# STM32N645 register map
File version: 1.0
CPU: CM55 r0p1, little endian, no MPU, FPU, vendor SysTick, 8 interrupt priority bits
Registers are 32-bit, read-write, reset 0x0 unless marked. A register's access mark holds for its fields unless they carry their own. Offsets are from the block's base; [hi:lo] are bit positions; {n}, {i} and the like mark numbered series.

## FDCAN1 — FDCAN register block
Base 0x4000A000
Same registers: FDCAN2 0x4000A400, FDCAN3 0x4000E800, FDCAN1_S 0x5000A000, FDCAN2_S 0x5000A400, FDCAN3_S 0x5000E800
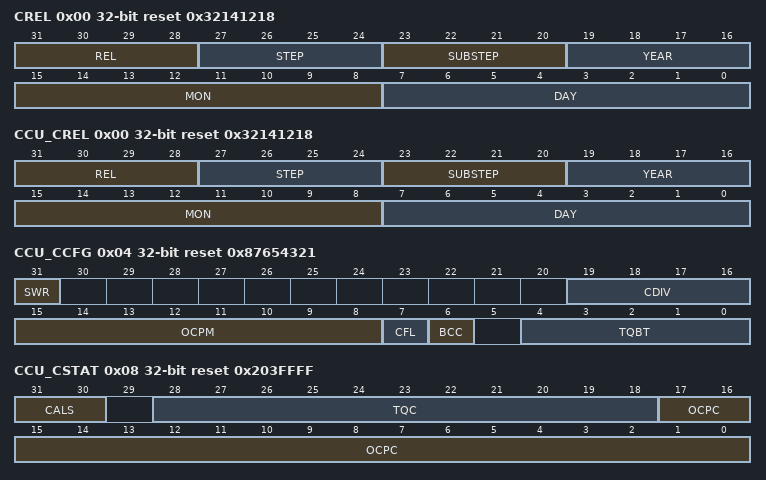
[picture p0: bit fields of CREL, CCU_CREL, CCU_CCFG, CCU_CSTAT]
0x00 CREL ro reset 0x32141218 — FDCAN core release register
  [31:28] REL — Core release = 3
  [27:24] STEP — Step of core release = 2
  [23:20] SUBSTEP — Sub-step of core release = 1
  [19:16] YEAR — Timestamp year = 4
  [15:8] MON — Timestamp month = 12
  [7:0] DAY — Timestamp day =18
0x00 CCU_CREL ro reset 0x32141218 (alternate view of CREL) — FDCAN core release register
  [31:28] REL — Core release = 1
  [27:24] STEP — Step of core release = 1
  [23:20] SUBSTEP — Sub-step of core release = 1
  [19:16] YEAR — Timestamp year =
  [15:8] MON — Timestamp month = 12
  [7:0] DAY — Timestamp day = 18
0x04 ENDN ro reset 0x87654321 — FDCAN Endian register
  [31:0] ETV — Endiannes Test value
0x04 CCU_CCFG reset 0x87654321 (alternate view of ENDN) — FDCAN Endian register
  [31] SWR — Software reset
  [19:16] CDIV — Clock divider
  [15:8] OCPM — Oscillator clock periods minimum
  [7] CFL — Calibration field length
  [6] BCC — Bypass clock calibration
  [4:0] TQBT — Time quanta per bit time
0x08 CCU_CSTAT ro reset 0x203FFFF — Calibration status register
  [31:30] CALS — Calibration state
  [28:18] TQC — Time quanta counter
  [17:0] OCPC — Oscillator clock period counter
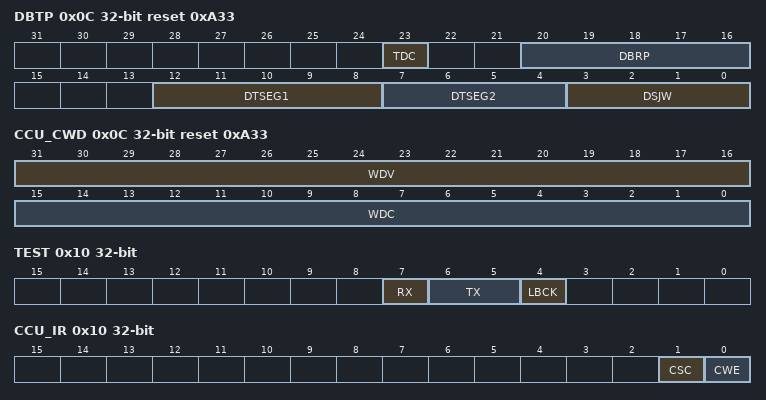
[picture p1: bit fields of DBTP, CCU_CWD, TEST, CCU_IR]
0x0C DBTP reset 0xA33 — FDCAN data bit timing and prescaler register
  [23] TDC — Transceiver delay compensation
  [20:16] DBRP — Data bitrate prescaler
  [12:8] DTSEG1 — Data time segment before sample point
  [7:4] DTSEG2 — Data time segment after sample point
  [3:0] DSJW — Synchronization jump width
0x0C CCU_CWD access per field reset 0xA33 (alternate view of DBTP) — FDCAN data bit timing and prescaler register
  [31:16] WDV ro — Watchdog value
  [15:0] WDC rw
0x10 TEST access per field — FDCAN test register
  [7] RX ro — Receive pin
  [6:5] TX rw — Control of transmit pin
  [4] LBCK rw — Loop back mode
0x10 CCU_IR (alternate view of TEST) — FDCAN test register
  [1] CSC — Calibration state changed
  [0] CWE — Calibration watchdog event
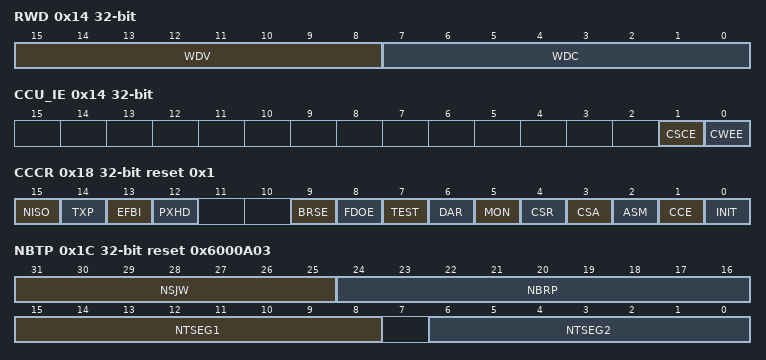
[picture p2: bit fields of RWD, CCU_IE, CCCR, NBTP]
0x14 RWD access per field — FDCAN RAM watchdog register
  [15:8] WDV ro — Watchdog value
  [7:0] WDC rw — Watchdog configuration
0x14 CCU_IE (alternate view of RWD) — FDCAN RAM watchdog register
  [1] CSCE — Calibration state changed enable
  [0] CWEE — Calibration watchdog event enable
0x18 CCCR access per field reset 0x1 — FDCAN CC control register
  [15] NISO rw — Non ISO operation
  [14] TXP rw — If this bit is set, the FDCAN pauses for two CAN bit times before starting the next transmission after successfully transmitting a frame.
  [13] EFBI rw — Edge filtering during bus integration
  [12] PXHD rw — Protocol exception handling disable
  [9] BRSE rw — FDCAN bitrate switching
  [8] FDOE rw — FD operation enable
  [7] TEST rw — Test mode enable
  [6] DAR rw — Disable automatic retransmission
  [5] MON rw — Bus monitoring mode
  [4] CSR rw — Clock stop request
  [3] CSA ro — Clock stop acknowledge
  [2] ASM rw — ASM restricted operation mode
  [1] CCE rw — Configuration change enable
  [0] INIT rw — Initialization
0x1C NBTP reset 0x6000A03 — FDCAN nominal bit timing and prescaler register
  [31:25] NSJW — Nominal (re)synchronization jump width
  [24:16] NBRP — Bitrate prescaler
  [15:8] NTSEG1 — Nominal time segment before sample point
  [6:0] NTSEG2 — Nominal time segment after sample point
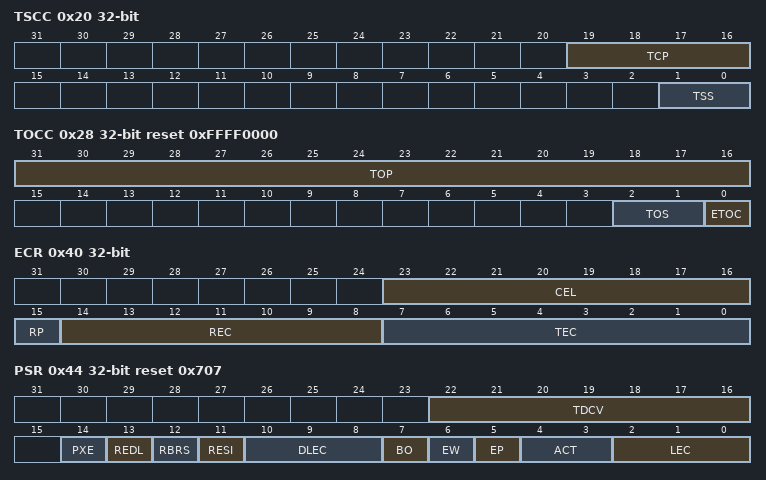
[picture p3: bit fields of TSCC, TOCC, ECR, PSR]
0x20 TSCC — FDCAN timestamp counter configuration register
  [19:16] TCP — Timestamp counter prescaler
  [1:0] TSS — Timestamp select
0x24 TSCV — FDCAN timestamp counter value register
  [15:0] TSC — Timestamp counter
0x28 TOCC reset 0xFFFF0000 — FDCAN timeout counter configuration register
  [31:16] TOP — Timeout period
  [2:1] TOS — Timeout select
  [0] ETOC — Enable timeout counter
0x2C TOCV reset 0xFFFF — FDCAN timeout counter value register
  [15:0] TOC — Timeout counter
0x40 ECR access per field — FDCAN error counter register
  [23:16] CEL rw — CAN error logging
  [15] RP ro — Receive error passive
  [14:8] REC ro — Receive error counter
  [7:0] TEC ro — Transmit error counter
0x44 PSR access per field reset 0x707 — FDCAN protocol status register
  [22:16] TDCV ro — Transmitter delay compensation value
  [14] PXE rw — Protocol exception event
  [13] REDL rw — Received FDCAN message
  [12] RBRS rw — BRS flag of last received FDCAN message
  [11] RESI rw — ESI flag of last received FDCAN message
  [10:8] DLEC ro — Data last error code
  [7] BO ro — Bus_Off status
  [6] EW ro — Warning status
  [5] EP ro — Error passive
  [4:3] ACT ro — Activity
  [2:0] LEC ro — Last error code
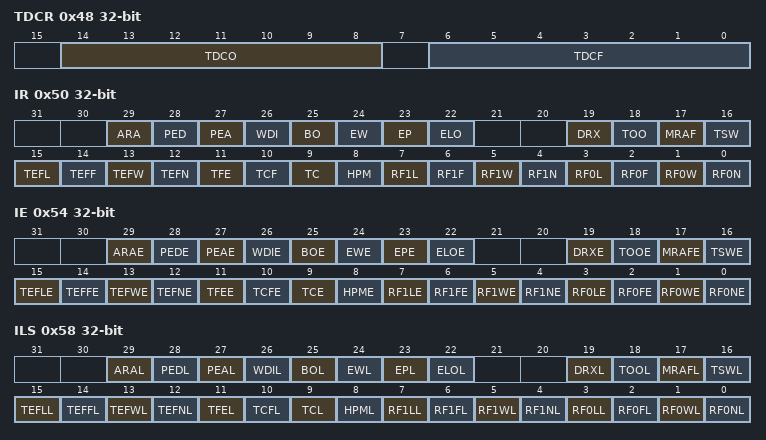
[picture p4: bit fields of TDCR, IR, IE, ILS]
0x48 TDCR — FDCAN transmitter delay compensation register
  [14:8] TDCO — Transmitter delay compensation offset
  [6:0] TDCF — Transmitter delay compensation filter window length
0x50 IR — FDCAN interrupt register
  [29] ARA — Access to reserved address
  [28] PED — Protocol error in data phase (data bit time is used)
  [27] PEA — Protocol error in arbitration phase (nominal bit time is used)
  [26] WDI — Watchdog interrupt
  [25] BO — Bus_Off status
  [24] EW — Warning status
  [23] EP — Error passive
  [22] ELO — Error logging overflow
  [19] DRX — Message stored to dedicated Rx buffer
  [18] TOO — Timeout occurred
  [17] MRAF — Message RAM access failure
  [16] TSW — Timestamp wraparound
  [15] TEFL — Tx event FIFO element lost
  [14] TEFF — Tx event FIFO full
  [13] TEFW — Tx event FIFO watermark reached
  [12] TEFN — Tx event FIFO new entry
  [11] TFE — Tx FIFO empty
  [10] TCF — Transmission cancellation finished
  [9] TC — Transmission completed
  [8] HPM — High priority message
  [7] RF1L — Rx FIFO 1 message lost
  [6] RF1F — Rx FIFO 1 full
  [5] RF1W — Rx FIFO 1 watermark reached
  [4] RF1N — Rx FIFO 1 new message
  [3] RF0L — Rx FIFO 0 message lost
  [2] RF0F — Rx FIFO 0 full
  [1] RF0W — Rx FIFO 0 watermark reached
  [0] RF0N — Rx FIFO 0 New message
0x54 IE — FDCAN interrupt enable register
  [29] ARAE — Access to Reserved address enable
  [28] PEDE — Protocol error in data phase enable
  [27] PEAE — Protocol error in Arbitration phase enable
  [26] WDIE — Watchdog interrupt enable
  [25] BOE — Bus_Off status
  [24] EWE — Warning status interrupt enable
  [23] EPE — Error passive interrupt enable
  [22] ELOE — Error logging overflow interrupt enable
  [19] DRXE — Message stored to dedicated Rx buffer interrupt enable
  [18] TOOE — Timeout occurred interrupt enable
  [17] MRAFE — Message RAM access failure interrupt enable
  [16] TSWE — Timestamp wraparound interrupt enable
  [15] TEFLE — Tx event FIFO element lost interrupt enable
  [14] TEFFE — Tx event FIFO full interrupt enable
  [13] TEFWE — Tx event FIFO watermark reached interrupt enable
  [12] TEFNE — Tx event FIFO new entry interrupt enable
  [11] TFEE — Tx FIFO empty interrupt enable
  [10] TCFE — Transmission cancellation finished interrupt enable
  [9] TCE — Transmission completed interrupt enable
  [8] HPME — High priority message interrupt enable
  [7] RF1LE — Rx FIFO 1 message lost interrupt enable
  [6] RF1FE — Rx FIFO 1 full interrupt enable
  [5] RF1WE — Rx FIFO 1 watermark reached interrupt enable
  [4] RF1NE — Rx FIFO 1 new message interrupt enable
  [3] RF0LE — Rx FIFO 0 message lost interrupt enable
  [2] RF0FE — Rx FIFO 0 full interrupt enable
  [1] RF0WE — Rx FIFO 0 watermark reached interrupt enable
  [0] RF0NE — Rx FIFO 0 new message interrupt enable
0x58 ILS — FDCAN interrupt line select register
  [29] ARAL — Access to reserved address line
  [28] PEDL — Protocol error in data phase line
  [27] PEAL — Protocol error in arbitration phase line
  [26] WDIL — Watchdog interrupt line
  [25] BOL — Bus_Off status
  [24] EWL — Warning status interrupt line
  [23] EPL — Error passive interrupt line
  [22] ELOL — Error logging overflow interrupt line
  [19] DRXL — Message stored to dedicated Rx buffer interrupt line
  [18] TOOL — Timeout occurred interrupt line
  [17] MRAFL — Message RAM access failure interrupt line
  [16] TSWL — Timestamp wraparound interrupt line
  [15] TEFLL — Tx event FIFO element Lost interrupt line
  [14] TEFFL — Tx event FIFO full interrupt line
  [13] TEFWL — Tx event FIFO watermark reached interrupt line
  [12] TEFNL — Tx event FIFO new entry interrupt line
  [11] TFEL — Tx FIFO empty interrupt line
  [10] TCFL — Transmission cancellation finished interrupt line
  [9] TCL — Transmission completed interrupt line
  [8] HPML — High priority message interrupt line
  [7] RF1LL — Rx FIFO 1 message lost interrupt line
  [6] RF1FL — Rx FIFO 1 full interrupt line
  [5] RF1WL — Rx FIFO 1 watermark reached interrupt line
  [4] RF1NL — Rx FIFO 1 new message interrupt line
  [3] RF0LL — Rx FIFO 0 message lost interrupt line
  [2] RF0FL — Rx FIFO 0 full interrupt line
  [1] RF0WL — Rx FIFO 0 watermark reached interrupt line
  [0] RF0NL — Rx FIFO 0 new message interrupt line
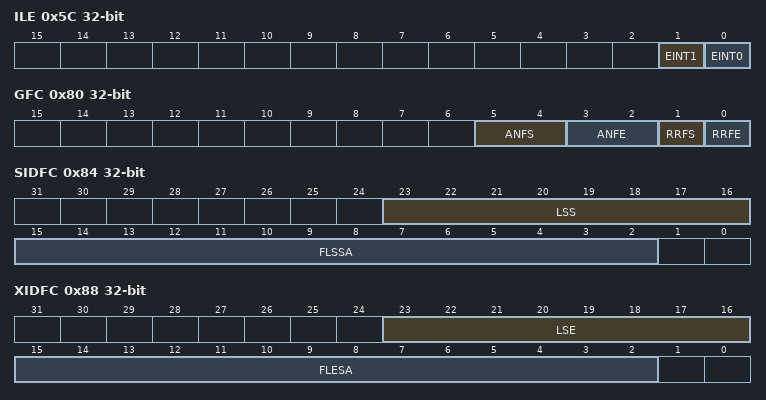
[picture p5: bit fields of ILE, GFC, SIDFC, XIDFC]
0x5C ILE — FDCAN interrupt line enable register
  [1] EINT1 — Enable interrupt line 1
  [0] EINT0 — Enable interrupt line 0
0x80 GFC — FDCAN global filter configuration register
  [5:4] ANFS — Accept non-matching frames standard
  [3:2] ANFE — Accept non-matching frames extended
  [1] RRFS — Reject remote frames standard
  [0] RRFE — Reject remote frames extended
0x84 SIDFC — FDCAN standard ID filter configuration register
  [23:16] LSS — List size standard
  [15:2] FLSSA — Filter list standard start address
0x88 XIDFC — FDCAN extended ID filter configuration register
  [23:16] LSE — List size extended
  [15:2] FLESA — Filter list extended start address
0x90 XIDAM reset 0x1FFFFFFF — FDCAN extended ID and mask register
  [28:0] EIDM — Extended ID Mask
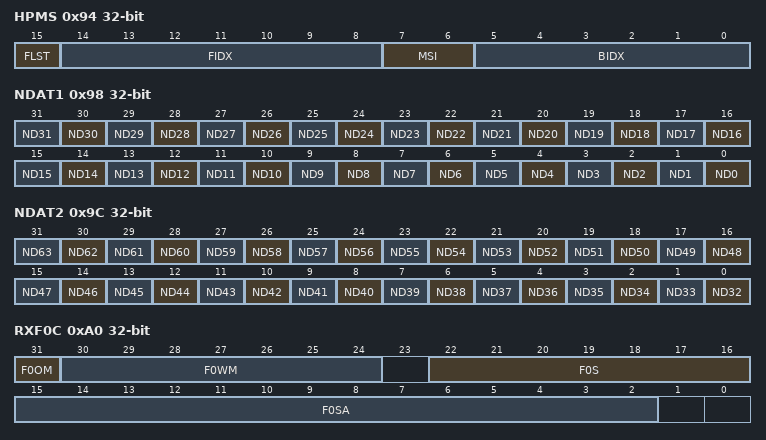
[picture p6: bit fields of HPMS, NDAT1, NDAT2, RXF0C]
0x94 HPMS ro — FDCAN high priority message status register
  [15] FLST — Filter list
  [14:8] FIDX — Filter index
  [7:6] MSI — Message storage indicator
  [5:0] BIDX — Buffer index
0x98 NDAT1 — FDCAN new data 1 register
  [n] ND{n} (n=0..31) — New data[31:0]
0x9C NDAT2 — FDCAN new data 2 register
  [n-32] ND{n} (n=32..63) — New data[63:32]
0xA0 RXF0C — FDCAN Rx FIFO 0 configuration register
  [31] F0OM — FIFO 0 operation mode
  [30:24] F0WM — FIFO 0 watermark
  [22:16] F0S — Rx FIFO 0 size
  [15:2] F0SA — Rx FIFO 0 start address
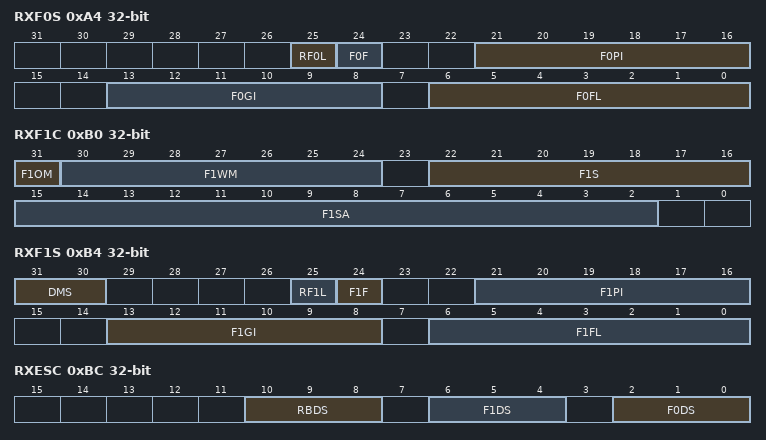
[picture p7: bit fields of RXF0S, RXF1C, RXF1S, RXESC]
0xA4 RXF0S — FDCAN Rx FIFO 0 status register
  [25] RF0L — Rx FIFO 0 message lost
  [24] F0F — Rx FIFO 0 full
  [21:16] F0PI — Rx FIFO 0 put index
  [13:8] F0GI — Rx FIFO 0 get index
  [6:0] F0FL — Rx FIFO 0 fill level
0xA8 RXF0A — FDCAN Rx FIFO 0 acknowledge register
  [5:0] F0AI — Rx FIFO 0 acknowledge index
0xAC RXBC — FDCAN Rx buffer configuration register
  [15:2] RBSA — Rx buffer start address
0xB0 RXF1C — FDCAN Rx FIFO 1 configuration register
  [31] F1OM — FIFO 1 operation mode
  [30:24] F1WM — Rx FIFO 1 watermark
  [22:16] F1S — Rx FIFO 1 size
  [15:2] F1SA — Rx FIFO 1 start address
0xB4 RXF1S ro — FDCAN Rx FIFO 1 status register
  [31:30] DMS — Debug message status
  [25] RF1L — Rx FIFO 1 message lost
  [24] F1F — Rx FIFO 1 full
  [21:16] F1PI — Rx FIFO 1 put index
  [13:8] F1GI — Rx FIFO 1 get index
  [6:0] F1FL — Rx FIFO 1 fill level
0xB8 RXF1A — FDCAN Rx FIFO 1 acknowledge register
  [5:0] F1AI — Rx FIFO 1 acknowledge index
0xBC RXESC ro — FDCAN Rx buffer element size configuration register
  [10:8] RBDS — Rx buffer data field size
  [6:4] F1DS — Rx FIFO 0 data field size
  [2:0] F0DS — Rx FIFO 1 data field size
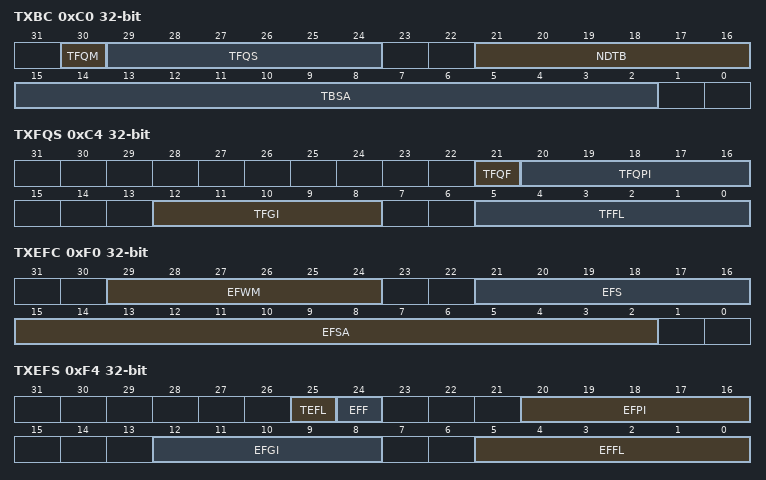
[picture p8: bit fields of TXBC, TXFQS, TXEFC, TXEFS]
0xC0 TXBC — FDCAN Tx buffer configuration register
  [30] TFQM — Tx FIFO/queue mode
  [29:24] TFQS — Transmit FIFO/queue size
  [21:16] NDTB — Number of dedicated transmit buffers
  [15:2] TBSA — Tx buffers start address
0xC4 TXFQS ro — FDCAN Tx FIFO/queue status register
  [21] TFQF — Tx FIFO/queue full
  [20:16] TFQPI — Tx FIFO/queue put index
  [12:8] TFGI — Tx FIFO get index.
  [5:0] TFFL — Tx FIFO free level
0xC8 TXESC ro — FDCAN Tx buffer element size configuration register
  [2:0] TBDS — Tx buffer data Field size:
0xCC TXBRP ro — FDCAN Tx buffer request pending register
  [31:0] TRP — Transmission request pending
0xD0 TXBAR — FDCAN Tx buffer add request register
  [31:0] AR — Add request
0xD4 TXBCR — FDCAN Tx buffer cancellation request register
  [31:0] CR — Cancellation request
0xD8 TXBTO ro — FDCAN Tx buffer transmission occurred register
  [31:0] TO — Transmission occurred
0xDC TXBCF ro — FDCAN Tx buffer cancellation finished register
  [31:0] CF — Cancellation finished
0xE0 TXBTIE — FDCAN Tx buffer transmission interrupt enable register
  [31:0] TIE — Transmission interrupt enable
0xE4 TXBCIE — FDCAN Tx buffer cancellation finished interrupt enable register
  [31:0] CFIE — Cancellation finished interrupt enable
0xF0 TXEFC — FDCAN Tx event FIFO configuration register
  [29:24] EFWM — Event FIFO watermark
  [21:16] EFS — Event FIFO size.
  [15:2] EFSA — Event FIFO start address
0xF4 TXEFS ro — FDCAN Tx event FIFO status register
  [25] TEFL — Tx event FIFO element lost
  [24] EFF — Event FIFO full
  [20:16] EFPI — Event FIFO put index
  [12:8] EFGI — Event FIFO get index
  [5:0] EFFL — Event FIFO fill level
0xF8 TXEFA — FDCAN Tx event FIFO acknowledge register
  [4:0] EFAI — Event FIFO acknowledge index
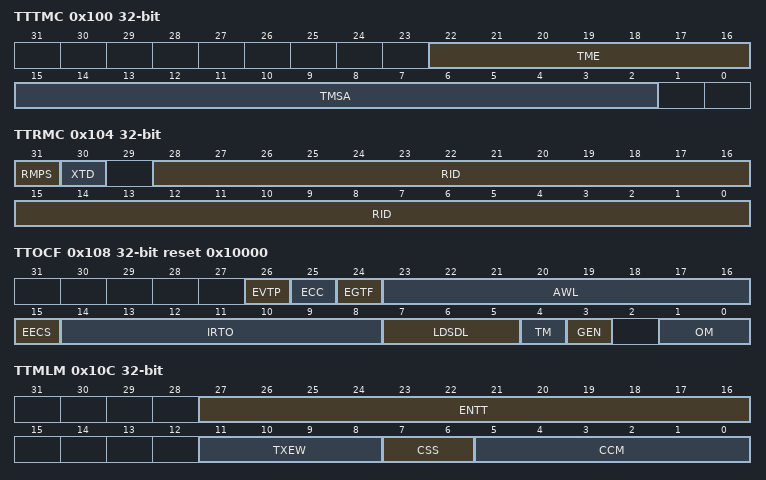
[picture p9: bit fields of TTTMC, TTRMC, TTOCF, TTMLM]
0x100 TTTMC — FDCAN TT trigger memory configuration register
  [22:16] TME — Trigger memory elements
  [15:2] TMSA — Trigger memory start address.
0x104 TTRMC — FDCAN TT reference message configuration register
  [31] RMPS — Reference message payload select
  [30] XTD — Extended identifier
  [28:0] RID — Reference identifier.
0x108 TTOCF reset 0x10000 — FDCAN TT operation configuration register
  [26] EVTP — Event trigger polarity.
  [25] ECC — Enable clock calibration.
  [24] EGTF — Enable global time filtering.
  [23:16] AWL — Application watchdog limit.
  [15] EECS — Enable external clock synchronization
  [14:8] IRTO — Initial reference trigger offset.
  [7:5] LDSDL — LD of synchronization deviation limit.
  [4] TM — Time master.
  [3] GEN — Gap enable.
  [1:0] OM — Operation mode.
0x10C TTMLM — FDCAN TT matrix limits register
  [27:16] ENTT — Expected number of Tx triggers
  [11:8] TXEW — Tx enable window
  [7:6] CSS — Cycle start synchronization
  [5:0] CCM — Cycle count Max
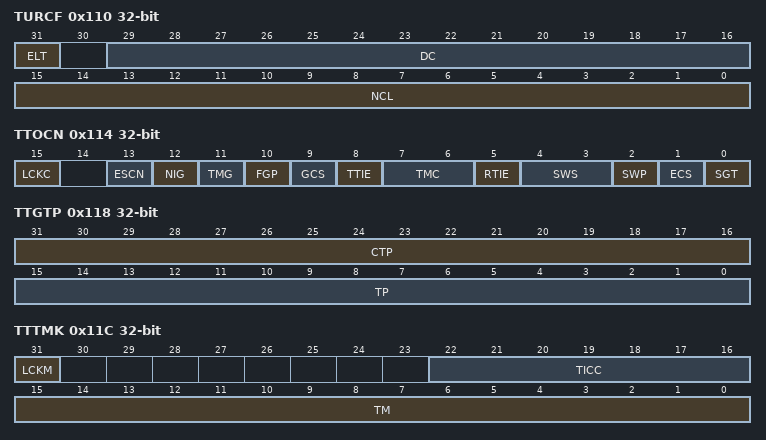
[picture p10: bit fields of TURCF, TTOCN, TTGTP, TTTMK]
0x110 TURCF — FDCAN TUR configuration register
  [31] ELT — Enable local time.
  [29:16] DC — Denominator configuration.
  [15:0] NCL — Numerator configuration low.
0x114 TTOCN access per field — FDCAN TT operation control register
  [15] LCKC ro — TT operation control register locked.
  [13] ESCN rw — External synchronization control
  [12] NIG rw — Next is gap.
  [11] TMG rw — Time mark gap.
  [10] FGP rw — Finish gap.
  [9] GCS rw — Gap control select
  [8] TTIE rw — Trigger time mark interrupt pulse enable
  [7:6] TMC rw — Register time mark compare.
  [5] RTIE rw — Register time mark interrupt pulse enable.
  [4:3] SWS rw — Stop watch source.
  [2] SWP rw — Stop watch polarity.
  [1] ECS rw — External clock synchronization.
  [0] SGT rw — Set global time.
0x118 TTGTP — FDCAN TT global time preset register
  [31:16] CTP — Cycle time target phase
  [15:0] TP — Time preset
0x11C TTTMK access per field — FDCAN TT time mark register
  [31] LCKM ro — TT time mark register locked
  [22:16] TICC rw — Time mark cycle code
  [15:0] TM rw — Time mark
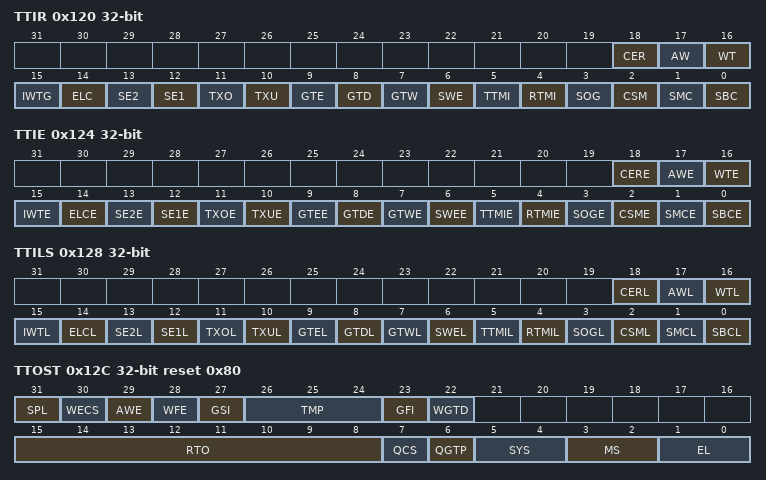
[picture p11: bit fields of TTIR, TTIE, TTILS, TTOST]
0x120 TTIR — FDCAN TT interrupt register
  [18] CER — Configuration error
  [17] AW — Application watchdog
  [16] WT — Watch trigger
  [15] IWTG — Initialization watch trigger
  [14] ELC — Error level changed
  [13] SE2 — Scheduling error 2
  [12] SE1 — Scheduling error 1
  [11] TXO — Tx count overflow
  [10] TXU — Tx count underflow
  [9] GTE — Global time error
  [8] GTD — Global time discontinuity
  [7] GTW — Global time wrap
  [6] SWE — Stop watch event
  [5] TTMI — Trigger time mark event internal
  [4] RTMI — Register time mark interrupt
  [3] SOG — Start of gap
  [2] CSM — Change of synchronization mode
  [1] SMC — Start of matrix cycle
  [0] SBC — Start of basic cycle
0x124 TTIE — FDCAN TT interrupt enable register
  [18] CERE — Configuration error interrupt enable
  [17] AWE — Application watchdog interrupt enable
  [16] WTE — Watch trigger interrupt enable
  [15] IWTE — Initialization watch trigger interrupt enable
  [14] ELCE — Change error level interrupt enable
  [13] SE2E — Scheduling error 2 interrupt enable
  [12] SE1E — Scheduling error 1 interrupt enable
  [11] TXOE — Tx count overflow interrupt enable
  [10] TXUE — Tx count underflow interrupt enable
  [9] GTEE — Global time error interrupt enable
  [8] GTDE — Global time discontinuity interrupt enable
  [7] GTWE — Global time wrap interrupt enable
  [6] SWEE — Stop watch event interrupt enable
  [5] TTMIE — Trigger time mark event internal interrupt enable
  [4] RTMIE — Register time mark interrupt enable
  [3] SOGE — Start of gap interrupt enable
  [2] CSME — Change of synchronization mode interrupt enable
  [1] SMCE — Start of matrix cycle interrupt enable
  [0] SBCE — Start of basic cycle interrupt enable
0x128 TTILS — FDCAN TT interrupt line select register
  [18] CERL — Configuration error interrupt line
  [17] AWL — Application watchdog interrupt line
  [16] WTL — Watch trigger interrupt line
  [15] IWTL — Initialization watch trigger interrupt line
  [14] ELCL — Change error level interrupt line
  [13] SE2L — Scheduling error 2 interrupt line
  [12] SE1L — Scheduling error 1 interrupt line
  [11] TXOL — Tx count overflow interrupt line
  [10] TXUL — Tx count underflow interrupt line
  [9] GTEL — Global time error interrupt line
  [8] GTDL — Global time discontinuity interrupt line
  [7] GTWL — Global time wrap interrupt line
  [6] SWEL — Stop watch event interrupt line
  [5] TTMIL — Trigger time mark event internal interrupt line
  [4] RTMIL — Register time mark interrupt line
  [3] SOGL — Start of gap interrupt line
  [2] CSML — Change of synchronization mode interrupt line
  [1] SMCL — Start of matrix cycle interrupt line
  [0] SBCL — Start of basic cycle interrupt line
0x12C TTOST ro reset 0x80 — FDCAN TT operation status register
  [31] SPL — Schedule phase lock
  [30] WECS — Wait for external clock synchronization.
  [29] AWE — Application watchdog event
  [28] WFE — Wait for event
  [27] GSI — Gap started indicator
  [26:24] TMP — Time master priority
  [23] GFI — Gap finished indicator
  [22] WGTD — Wait for global time discontinuity
  [15:8] RTO — Reference trigger offset
  [7] QCS — Quality of clock speed
  [6] QGTP — Quality of global time phase
  [5:4] SYS — Synchronization state
  [3:2] MS — Master state
  [1:0] EL — Error level
0x130 TURNA ro — FDCAN TUR numerator actual register
  [17:0] NAV — Numerator actual value
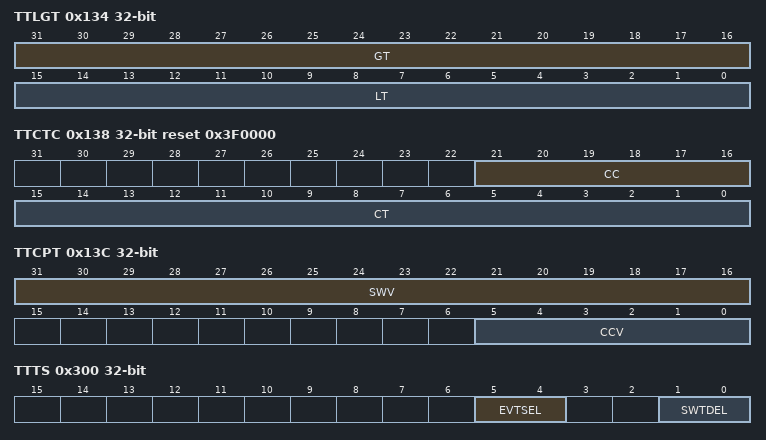
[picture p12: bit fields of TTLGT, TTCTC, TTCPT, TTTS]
0x134 TTLGT ro — FDCAN TT local and global time register
  [31:16] GT — Global time
  [15:0] LT — Local time
0x138 TTCTC ro reset 0x3F0000 — FDCAN TT cycle time and count register
  [21:16] CC — Cycle count
  [15:0] CT — Cycle time
0x13C TTCPT ro — FDCAN TT capture time register
  [31:16] SWV — Stop watch value
  [5:0] CCV — Cycle count value
0x140 TTCSM ro — FDCAN TT cycle sync mark register
  [15:0] CSM — Cycle sync mark
0x300 TTTS — FDCAN TT trigger select register
  [5:4] EVTSEL — Event trigger input selection
  [1:0] SWTDEL — Stop watch trigger input selection
